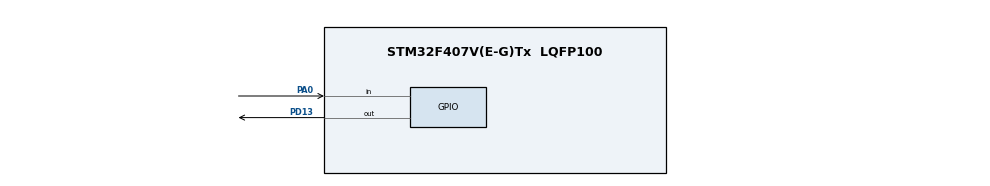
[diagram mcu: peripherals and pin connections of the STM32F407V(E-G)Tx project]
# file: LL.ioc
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Mcu.Family=STM32F4
Mcu.Name=STM32F407V(E-G)Tx
Mcu.Package=LQFP100
NVIC.PriorityGroup=NVIC_PRIORITYGROUP_4
PA0-WKUP.Signal=GPIO_Input
PD13.Signal=GPIO_Output
ProjectManager.HeapSize=0x200
ProjectManager.StackSize=0x400
ProjectManager.TargetToolchain=TrueSTUDIO
RCC.AHBFreq_Value=16000000
RCC.APB1Freq_Value=16000000
RCC.APB2Freq_Value=16000000
RCC.CortexFreq_Value=16000000
RCC.HSE_VALUE=25000000
RCC.HSI_VALUE=16000000
RCC.LSE_VALUE=32768
RCC.SYSCLKFreq_VALUE=16000000
RCC.VCOOutputFreq_Value=192000000
board=LL

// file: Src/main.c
/**
  ******************************************************************************
  * File Name          : main.c
  * Description        : Main program body
  ******************************************************************************
  ** This notice applies to any and all portions of this file
  * that are not between comment pairs USER CODE BEGIN and
  * USER CODE END. Other portions of this file, whether
  * inserted by the user or by software development tools
  * are owned by their respective copyright owners.
  *
  * COPYRIGHT(c) 2018 STMicroelectronics
  *
  * Redistribution and use in source and binary forms, with or without modification,
  * are permitted provided that the following conditions are met:
  *   1. Redistributions of source code must retain the above copyright notice,
  *      this list of conditions and the following disclaimer.
  *   2. Redistributions in binary form must reproduce the above copyright notice,
  *      this list of conditions and the following disclaimer in the documentation
  *      and/or other materials provided with the distribution.
  *   3. Neither the name of STMicroelectronics nor the names of its contributors
  *      may be used to endorse or promote products derived from this software
  *      without specific prior written permission.
  *
  * THIS SOFTWARE IS PROVIDED BY THE COPYRIGHT HOLDERS AND CONTRIBUTORS "AS IS"
  * AND ANY EXPRESS OR IMPLIED WARRANTIES, INCLUDING, BUT NOT LIMITED TO, THE
  * IMPLIED WARRANTIES OF MERCHANTABILITY AND FITNESS FOR A PARTICULAR PURPOSE ARE
  * DISCLAIMED. IN NO EVENT SHALL THE COPYRIGHT HOLDER OR CONTRIBUTORS BE LIABLE
  * FOR ANY DIRECT, INDIRECT, INCIDENTAL, SPECIAL, EXEMPLARY, OR CONSEQUENTIAL
  * DAMAGES (INCLUDING, BUT NOT LIMITED TO, PROCUREMENT OF SUBSTITUTE GOODS OR
  * SERVICES; LOSS OF USE, DATA, OR PROFITS; OR BUSINESS INTERRUPTION) HOWEVER
  * CAUSED AND ON ANY THEORY OF LIABILITY, WHETHER IN CONTRACT, STRICT LIABILITY,
  * OR TORT (INCLUDING NEGLIGENCE OR OTHERWISE) ARISING IN ANY WAY OUT OF THE USE
  * OF THIS SOFTWARE, EVEN IF ADVISED OF THE POSSIBILITY OF SUCH DAMAGE.
  *
  ******************************************************************************
  */

#include "main.h"

/* USER CODE BEGIN PV */
/* Private variables ---------------------------------------------------------*/

/* USER CODE END PV */

static void LL_Init(void);
void SystemClock_Config(void);
static void MX_GPIO_Init(void);

/* USER CODE BEGIN PFP */
/* Private function prototypes -----------------------------------------------*/

/* USER CODE END PFP */

int main(void)
{

  /* MCU Configuration----------------------------------------------------------*/

  /* Reset of all peripherals, Initializes the Flash interface and the Systick. */
  LL_Init();

  /* Configure the system clock */
  SystemClock_Config();

  /* Initialize all configured peripherals */
  MX_GPIO_Init();

  /* Infinite loop */
  while (1)
  {

  /* USER CODE BEGIN 3 */

	  LL_GPIO_TogglePin(GPIOD, LL_GPIO_PIN_13);

	  /* teszteleshez irt led villogtato kod
	  if (LL_GPIO_IsInputPinSet(GPIOA, LL_GPIO_PIN_0)) {
		  LL_GPIO_SetOutputPin(GPIOD, LL_GPIO_PIN_13);
	  }
	  else {
		  LL_GPIO_ResetOutputPin(GPIOD, LL_GPIO_PIN_13);
	  }
	  */

  }
  /* USER CODE END 3 */

}

static void LL_Init(void)
{

  NVIC_SetPriorityGrouping(NVIC_PRIORITYGROUP_4);

  /* System interrupt init*/
  /* MemoryManagement_IRQn interrupt configuration */
  NVIC_SetPriority(MemoryManagement_IRQn, NVIC_EncodePriority(NVIC_GetPriorityGrouping(),0, 0));
  /* BusFault_IRQn interrupt configuration */
  NVIC_SetPriority(BusFault_IRQn, NVIC_EncodePriority(NVIC_GetPriorityGrouping(),0, 0));
  /* UsageFault_IRQn interrupt configuration */
  NVIC_SetPriority(UsageFault_IRQn, NVIC_EncodePriority(NVIC_GetPriorityGrouping(),0, 0));
  /* SVCall_IRQn interrupt configuration */
  NVIC_SetPriority(SVCall_IRQn, NVIC_EncodePriority(NVIC_GetPriorityGrouping(),0, 0));
  /* DebugMonitor_IRQn interrupt configuration */
  NVIC_SetPriority(DebugMonitor_IRQn, NVIC_EncodePriority(NVIC_GetPriorityGrouping(),0, 0));
  /* PendSV_IRQn interrupt configuration */
  NVIC_SetPriority(PendSV_IRQn, NVIC_EncodePriority(NVIC_GetPriorityGrouping(),0, 0));
  /* SysTick_IRQn interrupt configuration */
  NVIC_SetPriority(SysTick_IRQn, NVIC_EncodePriority(NVIC_GetPriorityGrouping(),0, 0));

}

/** System Clock Configuration
*/
void SystemClock_Config(void)
{

  LL_FLASH_SetLatency(LL_FLASH_LATENCY_0);

  if(LL_FLASH_GetLatency() != LL_FLASH_LATENCY_0)
  {
  Error_Handler();
  }
  LL_PWR_SetRegulVoltageScaling(LL_PWR_REGU_VOLTAGE_SCALE1);

  LL_RCC_HSI_SetCalibTrimming(16);

  LL_RCC_HSI_Enable();

   /* Wait till HSI is ready */
  while(LL_RCC_HSI_IsReady() != 1)
  {

  }
  LL_RCC_SetAHBPrescaler(LL_RCC_SYSCLK_DIV_1);

  LL_RCC_SetAPB1Prescaler(LL_RCC_APB1_DIV_1);

  LL_RCC_SetAPB2Prescaler(LL_RCC_APB2_DIV_1);

  LL_RCC_SetSysClkSource(LL_RCC_SYS_CLKSOURCE_HSI);

   /* Wait till System clock is ready */
  while(LL_RCC_GetSysClkSource() != LL_RCC_SYS_CLKSOURCE_STATUS_HSI)
  {

  }
  LL_Init1msTick(16000000);

  LL_SYSTICK_SetClkSource(LL_SYSTICK_CLKSOURCE_HCLK);

  LL_SetSystemCoreClock(16000000);

  /* SysTick_IRQn interrupt configuration */
  NVIC_SetPriority(SysTick_IRQn, NVIC_EncodePriority(NVIC_GetPriorityGrouping(),0, 0));
}

/** Configure pins as
        * Analog
        * Input
        * Output
        * EVENT_OUT
        * EXTI
*/
static void MX_GPIO_Init(void)
{

  LL_GPIO_InitTypeDef GPIO_InitStruct;

  /* GPIO Ports Clock Enable */
  LL_AHB1_GRP1_EnableClock(LL_AHB1_GRP1_PERIPH_GPIOA);
  LL_AHB1_GRP1_EnableClock(LL_AHB1_GRP1_PERIPH_GPIOD);

  /**/
  LL_GPIO_ResetOutputPin(GPIOD, LL_GPIO_PIN_13);

  /**/
  GPIO_InitStruct.Pin = LL_GPIO_PIN_0;
  GPIO_InitStruct.Mode = LL_GPIO_MODE_INPUT;
  GPIO_InitStruct.Pull = LL_GPIO_PULL_NO;
  LL_GPIO_Init(GPIOA, &GPIO_InitStruct);

  /**/
  GPIO_InitStruct.Pin = LL_GPIO_PIN_13;
  GPIO_InitStruct.Mode = LL_GPIO_MODE_OUTPUT;
  GPIO_InitStruct.Speed = LL_GPIO_SPEED_FREQ_VERY_HIGH;
  GPIO_InitStruct.OutputType = LL_GPIO_OUTPUT_PUSHPULL;
  GPIO_InitStruct.Pull = LL_GPIO_PULL_NO;
  LL_GPIO_Init(GPIOD, &GPIO_InitStruct);

}

void _Error_Handler(char * file, int line)
{
  while(1)
  {
  }
}

/************************ (C) COPYRIGHT STMicroelectronics *****END OF FILE****/
